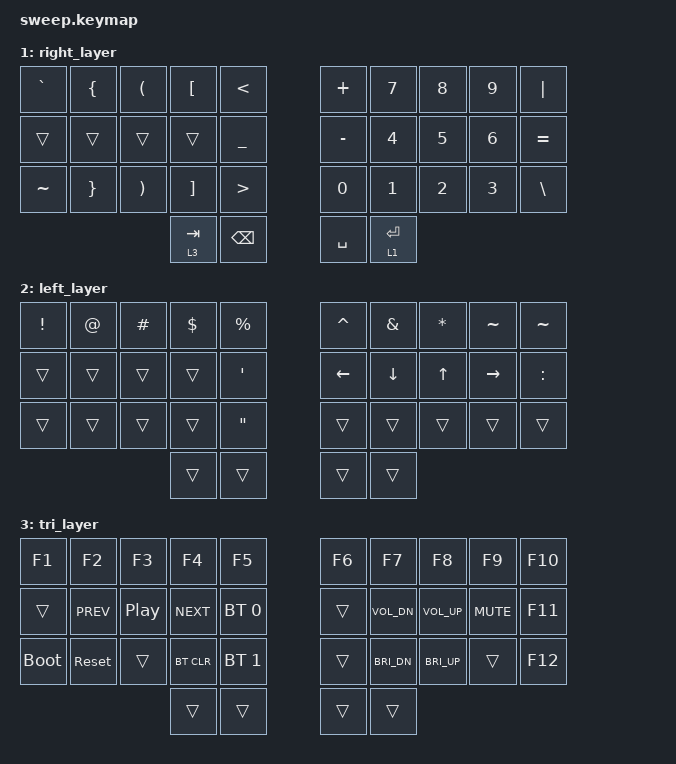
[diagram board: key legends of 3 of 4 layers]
// Copyright (c) 2022 The ZMK Contributors
// SPDX-License-Identifier: MIT

#include <behaviors.dtsi>
#include <dt-bindings/zmk/keys.h>
#include <dt-bindings/zmk/bt.h>

// Home row mods macro
#define HRML(k1,k2,k3,k4) &ht LCTRL k1  &ht LALT k2  &ht LGUI k3  &ht LSHFT k4
#define HRMR(k1,k2,k3,k4) &ht RCTRL k1  &ht RALT k2  &ht RGUI k3  &ht RSHFT k4

// Keycode macros
//#define KCOPY(k1) &ht LGUI(C) k1
//#define KPASTE(k1) &ht LGUI(V) k2
//#define KCUT(k1) &ht LGUI(X) k3

/ {
    behaviors {
        ht: hold_tap {
            compatible = "zmk,behavior-hold-tap";
            #binding-cells = <2>;
            flavor = "tap-preferred";
            tapping-term-ms = <220>;
            quick-tap-ms = <150>;
            require-prior-idle-ms = <100>;
            bindings = <&kp>, <&kp>;
        };
    };

    combos {
        compatible = "zmk,combos";
        combo_enter {
            timeout-ms = <50>;
            key-positions = <31 32>;
            bindings = <&kp RET>;
        };
        combo_escl {
            timeout-ms = <50>;
            key-positions = <12 13>;
            bindings = <&kp ESC>;
        };
        combo_escr {
            timeout-ms = <50>;
            key-positions = <16 17>;
            bindings = <&kp ESC>;
        };
        combo_caps {
            timeout-ms = <50>;
            key-positions = <6 7>;
            bindings = <&kp CAPS>;
        };
    };

    conditional_layers {
        compatible = "zmk,conditional-layers";
        tri_layer {
            if-layers = <1 2>;
            then-layer = <3>;
        };
    };

    keymap {
        compatible = "zmk,keymap";
        default_layer {
            bindings = <
        //╭──────────┬──────────┬──────────┬──────────┬──────────╮   ╭──────────┬──────────┬──────────┬──────────┬──────────╮
        //│  Q       │  W       │  E       │  R       │  T       │   │  Y       │  U       │  I       │  O       │  P       │
            &kp Q      &kp W      &kp E      &kp R      &kp T          &kp Y      &kp U      &kp I      &kp O      &kp P
        //├──────────┼──────────┼──────────┼──────────┼──────────┤   ├──────────┼──────────┼──────────┼──────────┼──────────┤
        //│  A       │  S       │  D       │  F       │  G       │   │  H       │  J       │  K       │  L       │ ; :      │
            HRML(A,        S,         D,         F)     &kp G          &kp H      HRMR(J,        K,         L,       SEMI)
        //├──────────┼──────────┼──────────┼──────────┼──────────┤   ├──────────┼──────────┼──────────┼──────────┼──────────┤
        //│  Z       │  X       │  C       │  V       │  B       │   │  N       │  M       │ , <      │ . >      │ / ?      │
            &kp Z      &kp X      &kp C      &kp V      &kp B          &kp N      &kp M      &kp COMMA  &kp DOT    &kp FSLH
        //╰──────────┴──────────┴──────────┼──────────┼──────────┤   ├──────────┼──────────┼──────────┴──────────┴──────────╯
                                             &lt 2 TAB  &kp BSPC       &kp SPACE  &lt 1 ENTER
        //                                 ╰──────────┴──────────╯   ╰──────────┴──────────╯
            >;
        };

        right_layer {
            bindings = <
        //╭──────────┬──────────┬──────────┬──────────┬──────────╮   ╭──────────┬──────────┬──────────┬──────────┬──────────╮
        //│  ` ~     │  {       │  (       │  [       │  <       │   │  +       │  7 &     │  8 *     │  9 (     │  |       │
            &kp GRAVE  &kp LBRC   &kp LPAR   &kp LBKT   &kp LT         &kp PLUS   &kp N7     &kp N8     &kp N9     &kp PIPE
        //├──────────┼──────────┼──────────┼──────────┼──────────┤   ├──────────┼──────────┼──────────┼──────────┼──────────┤
        //│          │          │          │          │  _       │   │  - _     │  4 $     │  5 %     │  6 ^     │  = +     │
            &trans     &trans     &trans     &trans     &kp UNDER      &kp MINUS  &kp N4     &kp N5     &kp N6     &kp EQUAL
        //├──────────┼──────────┼──────────┼──────────┼──────────┤   ├──────────┼──────────┼──────────┼──────────┼──────────┤
        //│  ~       │  }       │  )       │  ]       │  >       │   │  0 )     │  1 !     │  2 @     │  3 #     │  \ |     │
            &kp TILDE  &kp RBRC   &kp RPAR   &kp RBKT   &kp GT         &kp N0     &kp N1     &kp N2     &kp N3     &kp BSLH
        //╰──────────┴──────────┴──────────┼──────────┼──────────┤   ├──────────┼──────────┼──────────┴──────────┴──────────╯
                                             &lt 3 TAB  &kp BSPC       &kp SPACE  &lt 1 ENTER
        //                                 ╰──────────┴──────────╯   ╰──────────┴──────────╯
            >;
        };

        left_layer {
            bindings = <
        //╭──────────┬──────────┬──────────┬──────────┬──────────╮   ╭──────────┬──────────┬──────────┬──────────┬──────────╮
        //│  !       │  @       │  #       │  $       │  %       │   │  ^       │  &       │  *       │  ~       │  ~       │
            &kp EXCL   &kp AT     &kp HASH   &kp DLLR   &kp PRCNT      &kp CARET  &kp AMPS   &kp ASTRK  &kp TILDE  &kp TILDE
        //├──────────┼──────────┼──────────┼──────────┼──────────┤   ├──────────┼──────────┼──────────┼──────────┼──────────┤
        //│          │          │          │          │  ' "     │   │          │          │          │          │  :       │
            &trans     &trans     &trans     &trans     &kp SQT        &kp LEFT   &kp DOWN   &kp UP     &kp RIGHT  &kp COLON
        //├──────────┼──────────┼──────────┼──────────┼──────────┤   ├──────────┼──────────┼──────────┼──────────┼──────────┤
        //│          │          │          │          │  "       │   │          │          │          │          │          │
            &trans     &trans     &trans     &trans     &kp DQT        &trans     &trans     &trans     &trans     &trans
        //╰──────────┴──────────┴──────────┼──────────┼──────────┤   ├──────────┼──────────┼──────────┴──────────┴──────────╯
                                             &trans     &trans         &trans     &trans
        //                                 ╰──────────┴──────────╯   ╰──────────┴──────────╯
            >;
        };

        tri_layer {
            bindings = <
        //╭──────────┬──────────┬──────────┬──────────┬──────────╮   ╭──────────┬──────────┬──────────┬──────────┬──────────╮
        //│          │          │          │          │          │   │          │          │          │          │          │
            &kp F1     &kp F2     &kp F3     &kp F4     &kp F5         &kp F6     &kp F7     &kp F8     &kp F9     &kp F10
        //├──────────┼──────────┼──────────┼──────────┼──────────┤   ├──────────┼──────────┼──────────┼──────────┼──────────┤
        //│          │          │          │          │PROFILE 0 │   │          │          │          │          │          │
           &trans      &kp C_PREV &kp C_PP   &kp C_NEXT &bt BT_SEL 0    &trans   &kp C_VOL_DN &kp C_VOL_UP &kp K_MUTE &kp F11
        //├──────────┼──────────┼──────────┼──────────┼──────────┤   ├──────────┼──────────┼──────────┼──────────┼──────────┤
        //│BOOTLOADER│ RESET    │          │ CLEAR BT │PROFILE 1 │   │          │          │          │          │          │
          &bootloader &sys_reset  &trans    &bt BT_CLR &bt BT_SEL 1    &trans   &kp C_BRI_DN &kp C_BRI_UP &trans   &kp F12
        //╰──────────┴──────────┴──────────┼──────────┼──────────┤   ├──────────┼──────────┼──────────┴──────────┴──────────╯
                                             &trans     &trans         &trans     &trans
        //                                 ╰──────────┴──────────╯   ╰──────────┴──────────╯
            >;
        };
    };
};
